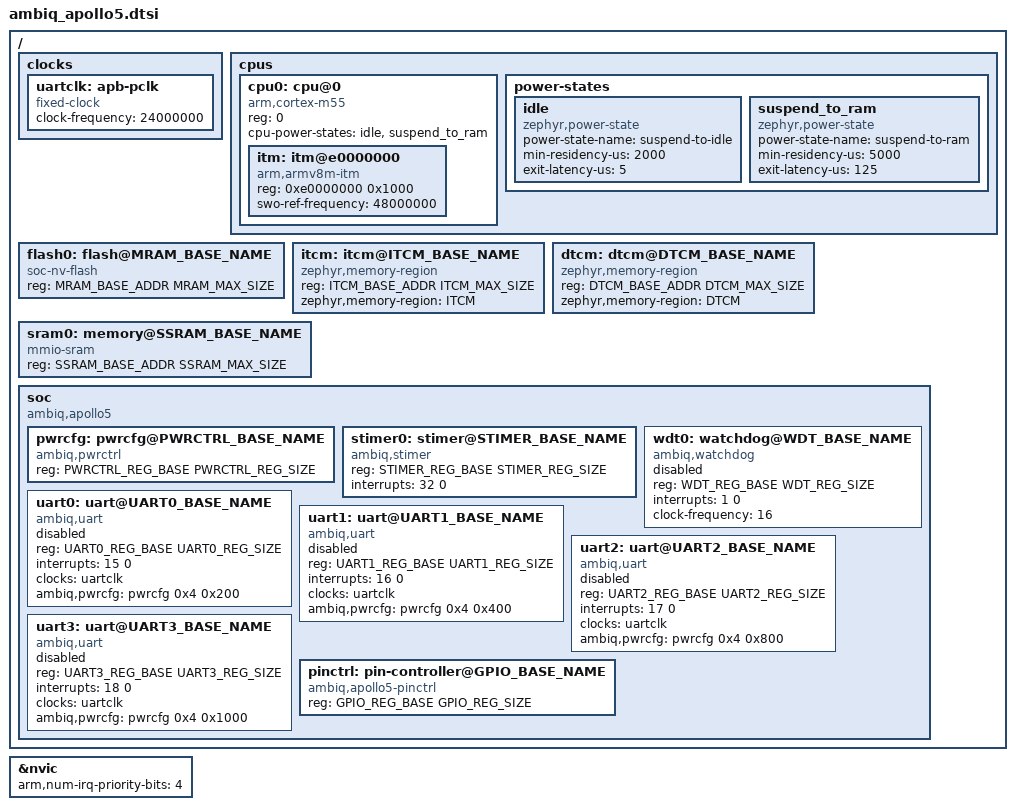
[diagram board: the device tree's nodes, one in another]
/* Copyright (c) 2024 Ambiq Micro Inc. */
/* SPDX-License-Identifier: Apache-2.0 */

#include <arm/armv8.1-m.dtsi>
#include <mem.h>
#include <apollo5/am_apollo5.h>
/ {
	clocks {
		uartclk: apb-pclk {
			compatible = "fixed-clock";
			clock-frequency = <24000000>;
			#clock-cells = <0>;
		};
	};

    cpus {
        #address-cells = <1>;
        #size-cells = <0>;

        cpu0: cpu@0 {
			device_type = "cpu";
			compatible = "arm,cortex-m55";
			reg = <0>;
			#address-cells = <1>;
			#size-cells = <1>;
            cpu-power-states = <&idle &suspend_to_ram>;

			itm: itm@e0000000 {
				compatible = "arm,armv8m-itm";
				reg = <0xe0000000 0x1000>;
				swo-ref-frequency = <48000000>;
			};
        };

        power-states {
            idle: idle {
                compatible = "zephyr,power-state";
                power-state-name = "suspend-to-idle";
                min-residency-us = <2000>;
                exit-latency-us = <5>;
            };

            suspend_to_ram: suspend_to_ram {
                compatible = "zephyr,power-state";
                power-state-name = "suspend-to-ram";
                min-residency-us = <5000>;
                exit-latency-us = <125>;
            };
        };
    };

    /* MRAM region */
    flash0: flash@MRAM_BASE_NAME {
        compatible = "soc-nv-flash";
        reg = <MRAM_BASE_ADDR MRAM_MAX_SIZE>;
    };

    /* TCM */
    itcm: itcm@ITCM_BASE_NAME {
        compatible = "zephyr,memory-region";
        reg = <ITCM_BASE_ADDR ITCM_MAX_SIZE>;
        zephyr,memory-region = "ITCM";
    };

    dtcm: dtcm@DTCM_BASE_NAME {
        compatible = "zephyr,memory-region";
        reg = <DTCM_BASE_ADDR DTCM_MAX_SIZE>;
        zephyr,memory-region = "DTCM";
    };

    /* SRAM */
    sram0: memory@SSRAM_BASE_NAME {
        compatible = "mmio-sram";
        reg = <SSRAM_BASE_ADDR SSRAM_MAX_SIZE>;
    };

    soc {
        compatible = "ambiq,apollo5", "ambiq,apollo5x", "simple-bus";

        pwrcfg: pwrcfg@PWRCTRL_BASE_NAME {
            compatible = "ambiq,pwrctrl";
            reg = <PWRCTRL_REG_BASE PWRCTRL_REG_SIZE>;
            #pwrcfg-cells = <2>;
        };

        stimer0: stimer@STIMER_BASE_NAME {
            compatible = "ambiq,stimer";
            reg = <STIMER_REG_BASE STIMER_REG_SIZE>;
            interrupts = <32 0>;
            status = "okay";
        };

        wdt0: watchdog@WDT_BASE_NAME {
            compatible = "ambiq,watchdog";
            reg = <WDT_REG_BASE WDT_REG_SIZE>;
            interrupts = <1 0>;
            clock-frequency = <16>;
            status = "disabled";
        };

		uart0: uart@UART0_BASE_NAME {
			compatible = "ambiq,uart", "arm,pl011";
			reg = <UART0_REG_BASE UART0_REG_SIZE>;
			interrupts = <15 0>;
			interrupt-names = "UART0";
			status = "disabled";
			clocks = <&uartclk>;
			ambiq,pwrcfg = <&pwrcfg 0x4 0x200>;
		};
		uart1: uart@UART1_BASE_NAME {
			compatible = "ambiq,uart", "arm,pl011";
			reg = <UART1_REG_BASE UART1_REG_SIZE>;
			interrupts = <16 0>;
			interrupt-names = "UART1";
			status = "disabled";
			clocks = <&uartclk>;
			ambiq,pwrcfg = <&pwrcfg 0x4 0x400>;
		};

		uart2: uart@UART2_BASE_NAME {
			compatible = "ambiq,uart", "arm,pl011";
			reg = <UART2_REG_BASE UART2_REG_SIZE>;
			interrupts = <17 0>;
			interrupt-names = "UART2";
			status = "disabled";
			clocks = <&uartclk>;
			ambiq,pwrcfg = <&pwrcfg 0x4 0x800>;
		};

		uart3: uart@UART3_BASE_NAME {
			compatible = "ambiq,uart", "arm,pl011";
			reg = <UART3_REG_BASE UART3_REG_SIZE>;
			interrupts = <18 0>;
			interrupt-names = "UART3";
			status = "disabled";
			clocks = <&uartclk>;
			ambiq,pwrcfg = <&pwrcfg 0x4 0x1000>;
		};

        pinctrl: pin-controller@GPIO_BASE_NAME {
            compatible = "ambiq,apollo5-pinctrl";
            reg = <GPIO_REG_BASE GPIO_REG_SIZE>;
            #address-cells = <1>;
            #size-cells = <0>;
        };

    };
};

&nvic {
    arm,num-irq-priority-bits = <4>;
};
